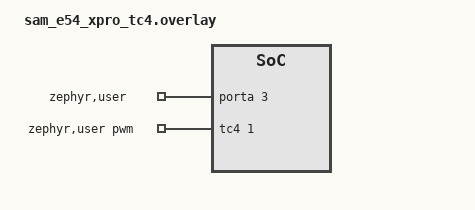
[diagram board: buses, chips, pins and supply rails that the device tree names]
/*
 * Copyright (c) 2025-2026 Microchip Technology Inc.
 * SPDX-License-Identifier: Apache-2.0
 */

/* connect PA23 to PA03 */

#define PWM_NODE     tc4
#define PWM_PINCTRL  tc4_pwm_default
#include "mchp_pwm_loopback_support.dtsi"

/ {
	zephyr,user {
		pwms = <&tc4 1 PWM_MSEC(1) 0>;
		gpios = <&porta 3 GPIO_ACTIVE_HIGH>;
	};
};

&porta {
	status = "okay";
};

&pinctrl {
	tc4_pwm_default: tc4_pwm_default {
		group1 {
			pinmux = <PA23E_TC4_WO1>;
		};
	};
};
